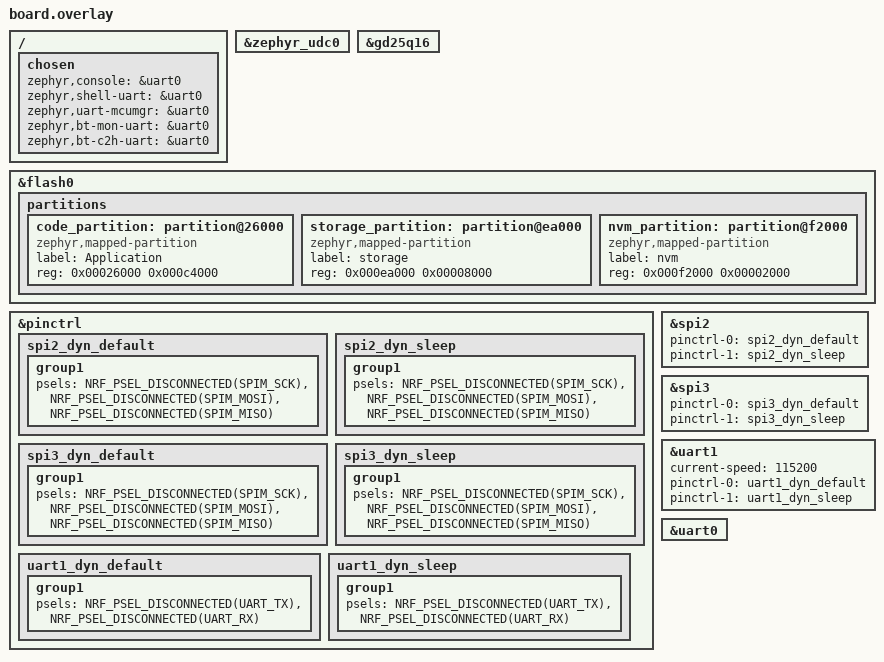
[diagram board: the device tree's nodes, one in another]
/ {
	chosen {
		zephyr,console = &uart0;
		zephyr,shell-uart = &uart0;
		zephyr,uart-mcumgr = &uart0;
		zephyr,bt-mon-uart = &uart0;
		zephyr,bt-c2h-uart = &uart0;
	};
};

&zephyr_udc0 {
	/delete-node/ board_cdc_acm_uart;
};


&gd25q16 {
	/delete-node/ partitions;
};

/delete-node/ &storage_partition;
/delete-node/ &code_partition;

&flash0 {
	partitions {
		code_partition: partition@26000 {
			compatible = "zephyr,mapped-partition";
			label = "Application";
			reg = <0x00026000 0x000c4000>;
		};

		storage_partition: partition@ea000 {
			compatible = "zephyr,mapped-partition";
			label = "storage";
			reg = <0x000ea000 0x00008000>;
		};

		nvm_partition: partition@f2000 {
			compatible = "zephyr,mapped-partition";
			label = "nvm";
			reg = <0x000f2000 0x00002000>;
		};
	};
};

// Extra bus instances enabled with all pins disconnected so CircuitPython can
// route them to arbitrary pins at runtime when a busio object is constructed:
// SPI2, SPI3 and UART1. (The board's fixed I2C0 and SPI1 instances stay as
// they are; UART0 is the console.)

&pinctrl {
	spi2_dyn_default: spi2_dyn_default {
		group1 {
			psels = <NRF_PSEL_DISCONNECTED(SPIM_SCK)>,
				<NRF_PSEL_DISCONNECTED(SPIM_MOSI)>,
				<NRF_PSEL_DISCONNECTED(SPIM_MISO)>;
		};
	};

	spi2_dyn_sleep: spi2_dyn_sleep {
		group1 {
			psels = <NRF_PSEL_DISCONNECTED(SPIM_SCK)>,
				<NRF_PSEL_DISCONNECTED(SPIM_MOSI)>,
				<NRF_PSEL_DISCONNECTED(SPIM_MISO)>;
		};
	};

	spi3_dyn_default: spi3_dyn_default {
		group1 {
			psels = <NRF_PSEL_DISCONNECTED(SPIM_SCK)>,
				<NRF_PSEL_DISCONNECTED(SPIM_MOSI)>,
				<NRF_PSEL_DISCONNECTED(SPIM_MISO)>;
		};
	};

	spi3_dyn_sleep: spi3_dyn_sleep {
		group1 {
			psels = <NRF_PSEL_DISCONNECTED(SPIM_SCK)>,
				<NRF_PSEL_DISCONNECTED(SPIM_MOSI)>,
				<NRF_PSEL_DISCONNECTED(SPIM_MISO)>;
		};
	};

	uart1_dyn_default: uart1_dyn_default {
		group1 {
			psels = <NRF_PSEL_DISCONNECTED(UART_TX)>,
				<NRF_PSEL_DISCONNECTED(UART_RX)>;
		};
	};

	uart1_dyn_sleep: uart1_dyn_sleep {
		group1 {
			psels = <NRF_PSEL_DISCONNECTED(UART_TX)>,
				<NRF_PSEL_DISCONNECTED(UART_RX)>;
		};
	};
};

&spi2 {
	pinctrl-0 = <&spi2_dyn_default>;
	pinctrl-1 = <&spi2_dyn_sleep>;
	pinctrl-names = "default", "sleep";
	status = "okay";
};

&spi3 {
	pinctrl-0 = <&spi3_dyn_default>;
	pinctrl-1 = <&spi3_dyn_sleep>;
	pinctrl-names = "default", "sleep";
	status = "okay";
};

&uart1 {
	current-speed = <115200>;
	pinctrl-0 = <&uart1_dyn_default>;
	pinctrl-1 = <&uart1_dyn_sleep>;
	pinctrl-names = "default", "sleep";
	status = "okay";
};

&uart0 {
    status = "okay";
};

#include "../../../app.overlay"
